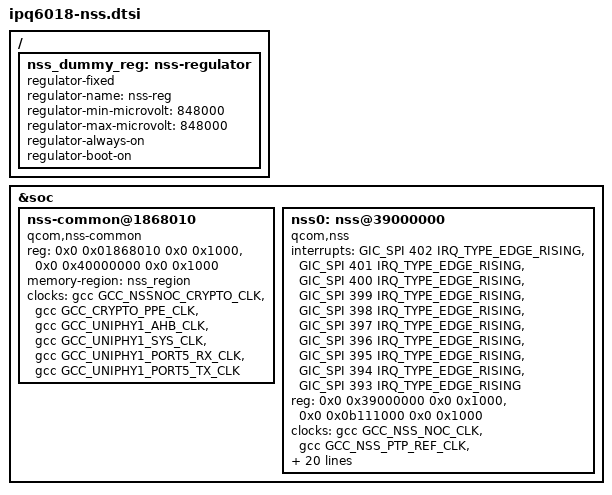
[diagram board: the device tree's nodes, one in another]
// SPDX-License-Identifier: GPL-2.0-only

/ {
	nss_dummy_reg: nss-regulator {
		compatible = "regulator-fixed";
		regulator-name = "nss-reg";
		regulator-min-microvolt = <848000>;
		regulator-max-microvolt = <848000>;
		regulator-always-on;
		regulator-boot-on;
	};
};

&soc {
	nss-common@1868010 {
		compatible = "qcom,nss-common";
		reg = <0x0 0x01868010 0x0 0x1000>,
		      <0x0 0x40000000 0x0 0x1000>;
		reg-names = "nss-misc-reset",
			    "nss-misc-reset-flag";
		memory-region = <&nss_region>;

		/*
		 * Clocks the NSS block requires while the firmware runs and
		 * that no host driver on the qca_edma/qca_ppe stack turns on.
		 * The UNIPHY domains are listed because firmware PPE init walks
		 * every port, while the PCS driver only clocks the domains
		 * with an active port. This SoC has two uniphys, not three.
		 */
		clocks = <&gcc GCC_NSSNOC_CRYPTO_CLK>,
			 <&gcc GCC_CRYPTO_PPE_CLK>,
			 <&gcc GCC_UNIPHY1_AHB_CLK>,
			 <&gcc GCC_UNIPHY1_SYS_CLK>,
			 <&gcc GCC_UNIPHY1_PORT5_RX_CLK>,
			 <&gcc GCC_UNIPHY1_PORT5_TX_CLK>;
		clock-names = "gcc_nssnoc_crypto_clk",
			      "gcc_crypto_ppe_clk",
			      "gcc_uniphy1_ahb_clk",
			      "gcc_uniphy1_sys_clk",
			      "gcc_uniphy1_port5_rx_clk",
			      "gcc_uniphy1_port5_tx_clk";
	};

	nss0: nss@39000000 {
		compatible = "qcom,nss";
		interrupts = <GIC_SPI 402 IRQ_TYPE_EDGE_RISING>,
			     <GIC_SPI 401 IRQ_TYPE_EDGE_RISING>,
			     <GIC_SPI 400 IRQ_TYPE_EDGE_RISING>,
			     <GIC_SPI 399 IRQ_TYPE_EDGE_RISING>,
			     <GIC_SPI 398 IRQ_TYPE_EDGE_RISING>,
			     <GIC_SPI 397 IRQ_TYPE_EDGE_RISING>,
			     <GIC_SPI 396 IRQ_TYPE_EDGE_RISING>,
			     <GIC_SPI 395 IRQ_TYPE_EDGE_RISING>,
			     <GIC_SPI 394 IRQ_TYPE_EDGE_RISING>,
			     <GIC_SPI 393 IRQ_TYPE_EDGE_RISING>;
		reg = <0x0 0x39000000 0x0 0x1000>,
		      <0x0 0x0b111000 0x0 0x1000>;
		reg-names = "nphys",
			    "qgic-phys";
		clocks = <&gcc GCC_NSS_NOC_CLK>,
			 <&gcc GCC_NSS_PTP_REF_CLK>,
			 <&gcc GCC_NSS_CSR_CLK>,
			 <&gcc GCC_NSS_CFG_CLK>,
			 <&gcc GCC_NSSNOC_QOSGEN_REF_CLK>,
			 <&gcc GCC_NSSNOC_SNOC_CLK>,
			 <&gcc GCC_NSSNOC_TIMEOUT_REF_CLK>,
			 <&gcc GCC_MEM_NOC_UBI32_CLK>,
			 <&gcc GCC_NSS_CE_AXI_CLK>,
			 <&gcc GCC_NSS_CE_APB_CLK>,
			 <&gcc GCC_NSSNOC_CE_AXI_CLK>,
			 <&gcc GCC_NSSNOC_CE_APB_CLK>,
			 <&gcc GCC_NSSNOC_UBI0_AHB_CLK>,
			 <&gcc GCC_UBI0_CORE_CLK>,
			 <&gcc GCC_UBI0_AHB_CLK>,
			 <&gcc GCC_UBI0_AXI_CLK>,
			 <&gcc GCC_UBI0_NC_AXI_CLK>,
			 <&gcc GCC_UBI0_UTCM_CLK>,
			 <&gcc GCC_SNOC_NSSNOC_CLK>;
		clock-names = "nss-noc-clk",
			      "nss-ptp-ref-clk",
			      "nss-csr-clk",
			      "nss-cfg-clk",
			      "nss-nssnoc-qosgen-ref-clk",
			      "nss-nssnoc-snoc-clk",
			      "nss-nssnoc-timeout-ref-clk",
			      "nss-mem-noc-ubi32-clk",
			      "nss-ce-axi-clk",
			      "nss-ce-apb-clk",
			      "nss-nssnoc-ce-axi-clk",
			      "nss-nssnoc-ce-apb-clk",
			      "nss-nssnoc-ahb-clk",
			      "nss-core-clk",
			      "nss-ahb-clk",
			      "nss-axi-clk",
			      "nss-nc-axi-clk",
			      "nss-utcm-clk",
			      "nss-snoc-nssnoc-clk";
		qcom,id = <0>;
		qcom,load-addr = <0x40000000>;
		qcom,max-frequency = <1497600000>;
		mx-supply = <&nss_dummy_reg>;
		npu-supply = <&nss_dummy_reg>;
	};
};
